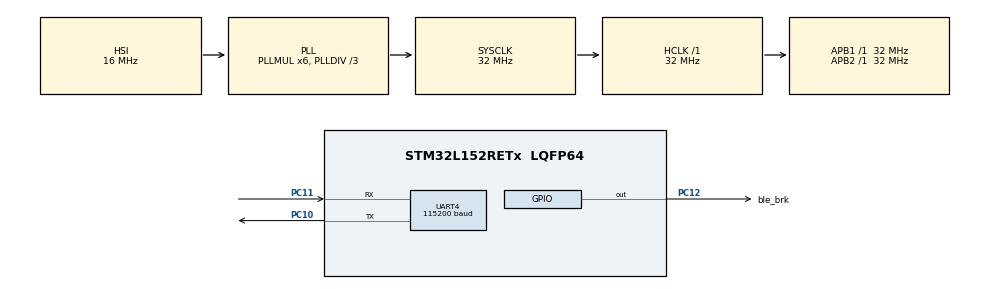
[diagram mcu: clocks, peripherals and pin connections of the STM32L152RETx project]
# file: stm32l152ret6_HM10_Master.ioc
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Dma.Request0=UART4_RX
Dma.UART4_RX.0.Direction=DMA_PERIPH_TO_MEMORY
Dma.UART4_RX.0.Instance=DMA2_Channel3
Dma.UART4_RX.0.MemDataAlignment=DMA_MDATAALIGN_BYTE
Dma.UART4_RX.0.MemInc=DMA_MINC_ENABLE
Dma.UART4_RX.0.Mode=DMA_NORMAL
Dma.UART4_RX.0.PeriphDataAlignment=DMA_PDATAALIGN_BYTE
Dma.UART4_RX.0.PeriphInc=DMA_PINC_DISABLE
Dma.UART4_RX.0.Priority=DMA_PRIORITY_LOW
Mcu.Family=STM32L1
Mcu.Name=STM32L152RETx
Mcu.Package=LQFP64
NVIC.DMA2_Channel3_IRQn=true\:1\:0\:true\:false\:true\:false\:true\:true
NVIC.PriorityGroup=NVIC_PRIORITYGROUP_4
NVIC.TIM2_IRQn=true\:0\:0\:false\:false\:true\:true\:true\:true
NVIC.TIM4_IRQn=true\:3\:0\:true\:false\:true\:true\:true\:true
NVIC.UART4_IRQn=true\:0\:0\:false\:false\:true\:true\:true\:true
PA13.Mode=Serial_Wire
PA13.Signal=SYS_JTMS-SWDIO
PA14.Mode=Serial_Wire
PA14.Signal=SYS_JTCK-SWCLK
PC10.Mode=Asynchronous
PC10.Signal=UART4_TX
PC11.Mode=Asynchronous
PC11.Signal=UART4_RX
PC12.GPIO_Label=ble_brk
PC12.Signal=GPIO_Output
ProjectManager.HeapSize=0x200
ProjectManager.StackSize=0x400
ProjectManager.TargetToolchain=STM32CubeIDE
RCC.48MHZClocksFreq_Value=48000000
RCC.AHBFreq_Value=32000000
RCC.APB1Freq_Value=32000000
RCC.APB1TimFreq_Value=32000000
RCC.APB2Freq_Value=32000000
RCC.APB2TimFreq_Value=32000000
RCC.HCLKFreq_Value=32000000
RCC.HSE_VALUE=24000000
RCC.HSI_VALUE=16000000
RCC.LSE_VALUE=32768
RCC.MSI_VALUE=2097000
RCC.PLLDIV=RCC_PLL_DIV3
RCC.PLLMUL=RCC_PLL_MUL6
RCC.SYSCLKFreq_VALUE=32000000
RCC.SYSCLKSource=RCC_SYSCLKSOURCE_PLLCLK
RCC.VCOOutputFreq_Value=96000000
TIM2.Prescaler=31
TIM4.Period=2500
TIM4.Prescaler=31999
UART4.BaudRate=115200
UART4.VirtualMode=Asynchronous
VP_TIM2_VS_ClockSourceINT.Mode=Internal
VP_TIM4_VS_ClockSourceINT.Mode=Internal
board=custom

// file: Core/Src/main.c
/* USER CODE BEGIN Header */
/**
  ******************************************************************************
  * @file           : main.c
  * @brief          : Main program body
  ******************************************************************************
  * @attention
  *
  * Copyright (c) 2024 STMicroelectronics.
  * All rights reserved.
  *
  * This software is licensed under terms that can be found in the LICENSE file
  * in the root directory of this software component.
  * If no LICENSE file comes with this software, it is provided AS-IS.
  *
  ******************************************************************************
  */
/* USER CODE END Header */
#include "main.h"

/* USER CODE BEGIN Includes */
#include <string.h>
#include "HM-10/recieveData.h"
#include "HM-10/HM10_Setup.h"
#include "utils/flashLog.h"
#include "st7789/st7789_Views/st7789_Data_Views.h"
/* USER CODE END Includes */

TIM_HandleTypeDef htim2;
TIM_HandleTypeDef htim4;

UART_HandleTypeDef huart4;
DMA_HandleTypeDef hdma_uart4_rx;

/* USER CODE BEGIN PV */
volatile uint8_t isConnected = 0;
volatile uint8_t isRSSI = 0;
volatile uint8_t reconnectingNum = 0;
char temp[10] = {'\0'};
char rssi[10] = {'\0'};
//RTC_TimeTypeDef sTime = {0};
uint16_t currPingTx = -1;
char * ping = "ping";
char currPingTxStr[20];
char currentTxBuf[50];
/* USER CODE END PV */

void SystemClock_Config(void);
static void MX_GPIO_Init(void);
static void MX_DMA_Init(void);
static void MX_TIM2_Init(void);
static void MX_UART4_Init(void);
static void MX_TIM4_Init(void);

int main(void)
{

  /* MCU Configuration--------------------------------------------------------*/

  /* Reset of all peripherals, Initializes the Flash interface and the Systick. */
  HAL_Init();

  /* Configure the system clock */
  SystemClock_Config();

  /* Initialize all configured peripherals */
  MX_GPIO_Init();
  MX_DMA_Init();
  MX_TIM2_Init();
  MX_UART4_Init();
  MX_TIM4_Init();
  /* USER CODE BEGIN 2 */
  HAL_TIM_Base_Start(&htim2);

  CMSIS_GPIO_init();
  CMSIS_SPI1_init();
  st7789_init();

  st7789_DrawStartScreen();
  if (setupMaster(&huart4, ble_brk_GPIO_Port, ble_brk_Pin) != OK) {
	  st7789_DrawErrScreen();
	  return HM10_ERROR;
  }

  st7789_DrawBleConnScreen();

  connectOtherHM10(&huart4);
  eraseDataFlash();
  isConnected = 1;

  st7789_DrawDataScreen();
  st7789_PrintString(293, 55, BLACK_st7789, WHITE_st7789, 1, &font_11x18, 1, "0");

  HAL_UARTEx_ReceiveToIdle_DMA(&huart4, rxBuf, rxBuf_SIZE);
  __HAL_DMA_DISABLE_IT(&hdma_uart4_rx, DMA_IT_HT);

  HAL_TIM_Base_Start_IT(&htim4);

  /* USER CODE END 2 */

  /* Infinite loop */
  while (1)
  {

  }
}

void SystemClock_Config(void)
{
  RCC_OscInitTypeDef RCC_OscInitStruct = {0};
  RCC_ClkInitTypeDef RCC_ClkInitStruct = {0};

  /** Configure the main internal regulator output voltage
  */
  __HAL_PWR_VOLTAGESCALING_CONFIG(PWR_REGULATOR_VOLTAGE_SCALE1);

  /** Initializes the RCC Oscillators according to the specified parameters
  * in the RCC_OscInitTypeDef structure.
  */
  RCC_OscInitStruct.OscillatorType = RCC_OSCILLATORTYPE_HSI;
  RCC_OscInitStruct.HSIState = RCC_HSI_ON;
  RCC_OscInitStruct.HSICalibrationValue = RCC_HSICALIBRATION_DEFAULT;
  RCC_OscInitStruct.PLL.PLLState = RCC_PLL_ON;
  RCC_OscInitStruct.PLL.PLLSource = RCC_PLLSOURCE_HSI;
  RCC_OscInitStruct.PLL.PLLMUL = RCC_PLL_MUL6;
  RCC_OscInitStruct.PLL.PLLDIV = RCC_PLL_DIV3;
  if (HAL_RCC_OscConfig(&RCC_OscInitStruct) != HAL_OK)
  {
    Error_Handler();
  }

  /** Initializes the CPU, AHB and APB buses clocks
  */
  RCC_ClkInitStruct.ClockType = RCC_CLOCKTYPE_HCLK|RCC_CLOCKTYPE_SYSCLK
                              |RCC_CLOCKTYPE_PCLK1|RCC_CLOCKTYPE_PCLK2;
  RCC_ClkInitStruct.SYSCLKSource = RCC_SYSCLKSOURCE_PLLCLK;
  RCC_ClkInitStruct.AHBCLKDivider = RCC_SYSCLK_DIV1;
  RCC_ClkInitStruct.APB1CLKDivider = RCC_HCLK_DIV1;
  RCC_ClkInitStruct.APB2CLKDivider = RCC_HCLK_DIV1;

  if (HAL_RCC_ClockConfig(&RCC_ClkInitStruct, FLASH_LATENCY_1) != HAL_OK)
  {
    Error_Handler();
  }
}

static void MX_TIM2_Init(void)
{

  TIM_ClockConfigTypeDef sClockSourceConfig = {0};
  TIM_MasterConfigTypeDef sMasterConfig = {0};

  htim2.Instance = TIM2;
  htim2.Init.Prescaler = 31;
  htim2.Init.CounterMode = TIM_COUNTERMODE_UP;
  htim2.Init.Period = 65535;
  htim2.Init.ClockDivision = TIM_CLOCKDIVISION_DIV1;
  htim2.Init.AutoReloadPreload = TIM_AUTORELOAD_PRELOAD_DISABLE;
  if (HAL_TIM_Base_Init(&htim2) != HAL_OK)
  {
    Error_Handler();
  }
  sClockSourceConfig.ClockSource = TIM_CLOCKSOURCE_INTERNAL;
  if (HAL_TIM_ConfigClockSource(&htim2, &sClockSourceConfig) != HAL_OK)
  {
    Error_Handler();
  }
  sMasterConfig.MasterOutputTrigger = TIM_TRGO_RESET;
  sMasterConfig.MasterSlaveMode = TIM_MASTERSLAVEMODE_DISABLE;
  if (HAL_TIMEx_MasterConfigSynchronization(&htim2, &sMasterConfig) != HAL_OK)
  {
    Error_Handler();
  }

}

static void MX_TIM4_Init(void)
{

  TIM_ClockConfigTypeDef sClockSourceConfig = {0};
  TIM_MasterConfigTypeDef sMasterConfig = {0};

  htim4.Instance = TIM4;
  htim4.Init.Prescaler = 31999;
  htim4.Init.CounterMode = TIM_COUNTERMODE_UP;
  htim4.Init.Period = 2000;
  htim4.Init.ClockDivision = TIM_CLOCKDIVISION_DIV1;
  htim4.Init.AutoReloadPreload = TIM_AUTORELOAD_PRELOAD_DISABLE;
  if (HAL_TIM_Base_Init(&htim4) != HAL_OK)
  {
    Error_Handler();
  }
  sClockSourceConfig.ClockSource = TIM_CLOCKSOURCE_INTERNAL;
  if (HAL_TIM_ConfigClockSource(&htim4, &sClockSourceConfig) != HAL_OK)
  {
    Error_Handler();
  }
  sMasterConfig.MasterOutputTrigger = TIM_TRGO_RESET;
  sMasterConfig.MasterSlaveMode = TIM_MASTERSLAVEMODE_DISABLE;
  if (HAL_TIMEx_MasterConfigSynchronization(&htim4, &sMasterConfig) != HAL_OK)
  {
    Error_Handler();
  }

}

static void MX_UART4_Init(void)
{

  huart4.Instance = UART4;
  huart4.Init.BaudRate = 115200;
  huart4.Init.WordLength = UART_WORDLENGTH_8B;
  huart4.Init.StopBits = UART_STOPBITS_1;
  huart4.Init.Parity = UART_PARITY_NONE;
  huart4.Init.Mode = UART_MODE_TX_RX;
  huart4.Init.HwFlowCtl = UART_HWCONTROL_NONE;
  huart4.Init.OverSampling = UART_OVERSAMPLING_16;
  if (HAL_UART_Init(&huart4) != HAL_OK)
  {
    Error_Handler();
  }

}

static void MX_DMA_Init(void)
{

  /* DMA controller clock enable */
  __HAL_RCC_DMA2_CLK_ENABLE();

  /* DMA interrupt init */
  /* DMA2_Channel3_IRQn interrupt configuration */
  HAL_NVIC_SetPriority(DMA2_Channel3_IRQn, 1, 0);
  HAL_NVIC_EnableIRQ(DMA2_Channel3_IRQn);

}

static void MX_GPIO_Init(void)
{
  GPIO_InitTypeDef GPIO_InitStruct = {0};

  /* GPIO Ports Clock Enable */
  __HAL_RCC_GPIOC_CLK_ENABLE();
  __HAL_RCC_GPIOA_CLK_ENABLE();

  /*Configure GPIO pin Output Level */
  HAL_GPIO_WritePin(ble_brk_GPIO_Port, ble_brk_Pin, GPIO_PIN_RESET);

  /*Configure GPIO pin : btn_Pin */
  GPIO_InitStruct.Pin = btn_Pin;
  GPIO_InitStruct.Mode = GPIO_MODE_IT_RISING;
  GPIO_InitStruct.Pull = GPIO_PULLUP;
  HAL_GPIO_Init(btn_GPIO_Port, &GPIO_InitStruct);

  /*Configure GPIO pin : ble_brk_Pin */
  GPIO_InitStruct.Pin = ble_brk_Pin;
  GPIO_InitStruct.Mode = GPIO_MODE_OUTPUT_PP;
  GPIO_InitStruct.Pull = GPIO_NOPULL;
  GPIO_InitStruct.Speed = GPIO_SPEED_FREQ_LOW;
  HAL_GPIO_Init(ble_brk_GPIO_Port, &GPIO_InitStruct);

  /* EXTI interrupt init*/
  HAL_NVIC_SetPriority(EXTI15_10_IRQn, 0, 0);
  HAL_NVIC_EnableIRQ(EXTI15_10_IRQn);

}

/* USER CODE BEGIN 4 */
void HAL_UARTEx_RxEventCallback(UART_HandleTypeDef *huart, uint16_t Size) {
	if (huart==&huart4) {
		UART4_RxCpltCallback(huart, Size);
	}
}

void HAL_TIM_PeriodElapsedCallback(TIM_HandleTypeDef *htim) {
	if(htim==&htim4) {
		if (isConnected) {
			if (isRSSI == 0) {
				HAL_UART_Transmit(&huart4, getCommand(RSSI_GET), strlen((char *) getCommand(RSSI_GET)), 0x1000);
			}
			else {
				transmitPing();
			}
		}
		else if (isConnected == 0) {
			reconnectOtherHM10(&huart4);
			/* Display successful connection to user */
			st7789_FillRect(170, 10, 150, 20, WHITE_st7789);
			/* Clear previous received data stats */
			st7789_FillRect(160, 165, 150, 20, WHITE_st7789);
			writeStringToDataFlash((char *) " Conn");
			/* Change connection status */
			st7789_PrintString(220, 10, BLACK_st7789, GREEN_st7789, 1, &font_11x18, 1, "Сопряжен");
			reconnectingNum++;
			char recStr[4];
			sprintf(recStr, "%d", reconnectingNum);
			if (reconnectingNum < 10) {
				st7789_PrintString(293, 55, BLACK_st7789, WHITE_st7789, 1, &font_11x18, 1, recStr);
			}
			else {
				st7789_PrintString(280, 55, BLACK_st7789, WHITE_st7789, 1, &font_11x18, 1, recStr);
			}
			isConnected = 1;
			HAL_UARTEx_ReceiveToIdle_DMA(&huart4, rxBuf, rxBuf_SIZE);
			__HAL_DMA_DISABLE_IT(&hdma_uart4_rx, DMA_IT_HT);
		}
	}
}

void HAL_GPIO_EXTI_Callback(uint16_t GPIO_Pin) {
	if(GPIO_Pin == btn_Pin) {
		checkConnection(&huart4);
	}
}

void transmitPing() {
	currPingTx++;
	snprintf(currPingTxStr, sizeof(currPingTxStr), "%d", currPingTx);
	strcat(currentTxBuf, ping);
	strcat(currentTxBuf, currPingTxStr);

	HAL_UART_Transmit(&huart4, (uint8_t *) currentTxBuf, 100, 0xFFFF);
	memset(currentTxBuf, 0, 50);
}
/* USER CODE END 4 */

void Error_Handler(void)
{
  __disable_irq();
  while (1)
  {
  }
}
